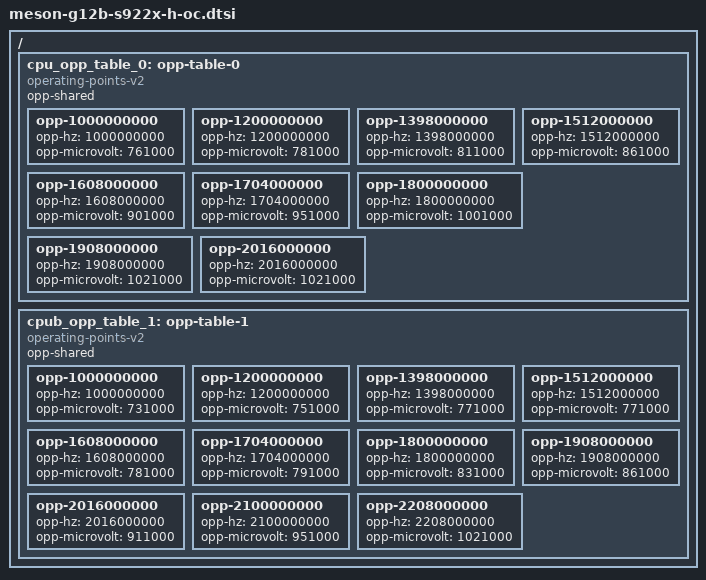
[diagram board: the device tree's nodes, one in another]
// SPDX-License-Identifier: (GPL-2.0+ OR MIT)
/*
 * Author: Flippy <flippy@sina.com>
 */

/ {
        cpu_opp_table_0: opp-table-0 {
                compatible = "operating-points-v2";
                opp-shared;

                opp-1000000000 {
                        opp-hz = /bits/ 64 <1000000000>;
                        opp-microvolt = <761000>;
                };

                opp-1200000000 {
                        opp-hz = /bits/ 64 <1200000000>;
                        opp-microvolt = <781000>;
                };

                opp-1398000000 {
                        opp-hz = /bits/ 64 <1398000000>;
                        opp-microvolt = <811000>;
                };

                opp-1512000000 {
                        opp-hz = /bits/ 64 <1512000000>;
                        opp-microvolt = <861000>;
                };

                opp-1608000000 {
                        opp-hz = /bits/ 64 <1608000000>;
                        opp-microvolt = <901000>;
                };

                opp-1704000000 {
                        opp-hz = /bits/ 64 <1704000000>;
                        opp-microvolt = <951000>;
                };

                opp-1800000000 {
                        opp-hz = /bits/ 64 <1800000000>;
                        opp-microvolt = <1001000>;
                };

                opp-1908000000 {
                        opp-hz = /bits/ 64 <1908000000>;
                        opp-microvolt = < 1021000>;
                };

                opp-2016000000 {
                        opp-hz = /bits/ 64 <2016000000>;
                        opp-microvolt = < 1021000>;
                };

        };

        cpub_opp_table_1: opp-table-1 {
                compatible = "operating-points-v2";
                opp-shared;

                opp-1000000000 {
                        opp-hz = /bits/ 64 <1000000000>;
                        opp-microvolt = <731000>;
                };

                opp-1200000000 {
                        opp-hz = /bits/ 64 <1200000000>;
                        opp-microvolt = <751000>;
                };

                opp-1398000000 {
                        opp-hz = /bits/ 64 <1398000000>;
                        opp-microvolt = <771000>;
                };

                opp-1512000000 {
                        opp-hz = /bits/ 64 <1512000000>;
                        opp-microvolt = <771000>;
                };

                opp-1608000000 {
                        opp-hz = /bits/ 64 <1608000000>;
                        opp-microvolt = <781000>;
                };

                opp-1704000000 {
                        opp-hz = /bits/ 64 <1704000000>;
                        opp-microvolt = <791000>;
                };

                opp-1800000000 {
                        opp-hz = /bits/ 64 <1800000000>;
                        opp-microvolt = <831000>;
                };

                opp-1908000000 {
                        opp-hz = /bits/ 64 <1908000000>;
                        opp-microvolt = <861000>;
                };

                opp-2016000000 {
                        opp-hz = /bits/ 64 <2016000000>;
                        opp-microvolt = <911000>;
                };

                opp-2100000000 {
                        opp-hz = /bits/ 64 <2100000000>;
                        opp-microvolt = <951000>;
                };

                opp-2208000000 {
                        opp-hz = /bits/ 64 <2208000000>;
                        opp-microvolt = <1021000>;
                };
        };
};
